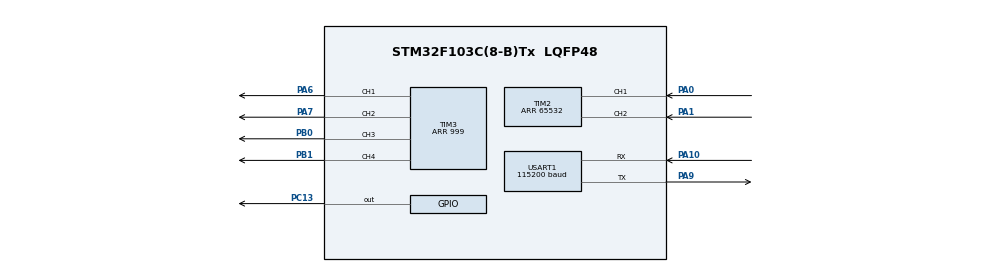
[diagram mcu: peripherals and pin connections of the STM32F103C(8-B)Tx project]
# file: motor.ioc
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Dma.Request0=USART1_RX
Dma.USART1_RX.0.Direction=DMA_PERIPH_TO_MEMORY
Dma.USART1_RX.0.Instance=DMA1_Channel5
Dma.USART1_RX.0.MemDataAlignment=DMA_MDATAALIGN_BYTE
Dma.USART1_RX.0.MemInc=DMA_MINC_ENABLE
Dma.USART1_RX.0.Mode=DMA_CIRCULAR
Dma.USART1_RX.0.PeriphDataAlignment=DMA_PDATAALIGN_BYTE
Dma.USART1_RX.0.PeriphInc=DMA_PINC_DISABLE
Dma.USART1_RX.0.Priority=DMA_PRIORITY_LOW
Mcu.Family=STM32F1
Mcu.Name=STM32F103C(8-B)Tx
Mcu.Package=LQFP48
NVIC.DMA1_Channel5_IRQn=true\:0\:0\:false\:false\:true\:false\:true\:true
NVIC.PriorityGroup=NVIC_PRIORITYGROUP_4
NVIC.USART1_IRQn=true\:0\:0\:false\:false\:true\:true\:true\:true
PA0-WKUP.Signal=S_TIM2_CH1_ETR
PA1.Signal=S_TIM2_CH2
PA10.GPIO_PuPd=GPIO_PULLUP
PA10.Mode=Asynchronous
PA10.Signal=USART1_RX
PA13.Mode=Serial_Wire
PA13.Signal=SYS_JTMS-SWDIO
PA14.Mode=Serial_Wire
PA14.Signal=SYS_JTCK-SWCLK
PA6.Signal=S_TIM3_CH1
PA7.Signal=S_TIM3_CH2
PA9.Mode=Asynchronous
PA9.Signal=USART1_TX
PB0.Signal=S_TIM3_CH3
PB1.Signal=S_TIM3_CH4
PC13-TAMPER-RTC.GPIO_ModeDefaultOutputPP=GPIO_MODE_OUTPUT_OD
PC13-TAMPER-RTC.GPIO_PuPd=GPIO_NOPULL
PC13-TAMPER-RTC.Signal=GPIO_Output
ProjectManager.HeapSize=0x200
ProjectManager.StackSize=0x400
ProjectManager.TargetToolchain=CMake
RCC.APB1Freq_Value=8000000
RCC.APB2Freq_Value=8000000
SH.S_TIM2_CH1_ETR.0=TIM2_CH1,Encoder_Interface
SH.S_TIM2_CH2.0=TIM2_CH2,Encoder_Interface
SH.S_TIM3_CH1.0=TIM3_CH1,PWM Generation1 CH1
SH.S_TIM3_CH2.0=TIM3_CH2,PWM Generation2 CH2
SH.S_TIM3_CH3.0=TIM3_CH3,PWM Generation3 CH3
SH.S_TIM3_CH4.0=TIM3_CH4,PWM Generation4 CH4
TIM2.EncoderMode=TIM_ENCODERMODE_TI12
TIM2.Period=65532
TIM3.Channel-PWM\ Generation1\ CH1=TIM_CHANNEL_1
TIM3.Channel-PWM\ Generation2\ CH2=TIM_CHANNEL_2
TIM3.Channel-PWM\ Generation3\ CH3=TIM_CHANNEL_3
TIM3.Channel-PWM\ Generation4\ CH4=TIM_CHANNEL_4
TIM3.Period=999
USART1.BaudRate=115200
USART1.VirtualMode=VM_ASYNC
VP_TIM3_VS_ClockSourceINT.Mode=Internal
board=custom

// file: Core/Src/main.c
/* USER CODE BEGIN Header */
/**
  ******************************************************************************
  * @file           : main.c
  * @brief          : Main program body
  ******************************************************************************
  * @attention
  *
  * Copyright (c) 2026 STMicroelectronics.
  * All rights reserved.
  *
  * This software is licensed under terms that can be found in the LICENSE file
  * in the root directory of this software component.
  * If no LICENSE file comes with this software, it is provided AS-IS.
  *
  ******************************************************************************
  */
/* USER CODE END Header */
#include "main.h"

/* USER CODE BEGIN Includes */

#include "USART_self.h"

/* USER CODE END Includes */

TIM_HandleTypeDef htim2;
TIM_HandleTypeDef htim3;

UART_HandleTypeDef huart1;
DMA_HandleTypeDef hdma_usart1_rx;

/* USER CODE BEGIN PV */

static USART_T uart1;

/* USER CODE END PV */

void SystemClock_Config(void);
static void MX_GPIO_Init(void);
static void MX_DMA_Init(void);
static void MX_USART1_UART_Init(void);
static void MX_TIM2_Init(void);
static void MX_TIM3_Init(void);

/* USER CODE BEGIN 0 */

//void HAL_UART_RxCpltCallback(UART_HandleTypeDef *huart){
//  USART_RxCpltHandler(huart);
//}

/* USER CODE END 0 */

int main(void)
{

  /* MCU Configuration--------------------------------------------------------*/

  /* Reset of all peripherals, Initializes the Flash interface and the Systick. */
  HAL_Init();

  /* Configure the system clock */
  SystemClock_Config();

  /* Initialize all configured peripherals */
  MX_GPIO_Init();
  MX_DMA_Init();
  MX_USART1_UART_Init();
  MX_TIM2_Init();
  MX_TIM3_Init();
  /* USER CODE BEGIN 2 */

  USART_Init(&uart1,&huart1);

  //uint8_t test_data[4]={0x01,0x02,0x03,0x04};

  HAL_TIM_Encoder_Start(&htim2, TIM_CHANNEL_1);
  HAL_TIM_Encoder_Start(&htim2, TIM_CHANNEL_2);
  uint32_t TIME=0;
  uint16_t CNT;
  float Send_t;
  float Send;
  float speed;

  /* USER CODE END 2 */

  /* Infinite loop */
  /* USER CODE BEGIN WHILE */
  while (1)
  {

    //USART_Send(&uart1,test_data,4);

    //int i=USART_ReadByte(&uart1);
    //if(i>0) {
    //  uint8_t data=i;
    //  USART_Send(&uart1,&data,1);
    //}

    //SendVOFA(&uart1,0x00,1);

  //if (HAL_GetTick()>=TIME) {
  //  TIME=TIME+10;
  //
  //  CNT=__HAL_TIM_GET_COUNTER(&htim2);
  //
  //
  //  Send=(float)CNT/1330*360;
  //
  //  speed=(Send-Send_t)/0.01;
  //
  //  SendVOFA(&uart1,&speed,1);
  //
  //  Send_t=Send;
  //}

    int a=USART_ReadByte(&uart1);
    if (a>0) {
      uint8_t send=a;
      USART_Send(&uart1,&send,1);
    }

    /* USER CODE END WHILE */

  }
}

void SystemClock_Config(void)
{
  RCC_OscInitTypeDef RCC_OscInitStruct = {0};
  RCC_ClkInitTypeDef RCC_ClkInitStruct = {0};

  /** Initializes the RCC Oscillators according to the specified parameters
  * in the RCC_OscInitTypeDef structure.
  */
  RCC_OscInitStruct.OscillatorType = RCC_OSCILLATORTYPE_HSI;
  RCC_OscInitStruct.HSIState = RCC_HSI_ON;
  RCC_OscInitStruct.HSICalibrationValue = RCC_HSICALIBRATION_DEFAULT;
  RCC_OscInitStruct.PLL.PLLState = RCC_PLL_NONE;
  if (HAL_RCC_OscConfig(&RCC_OscInitStruct) != HAL_OK)
  {
    Error_Handler();
  }

  /** Initializes the CPU, AHB and APB buses clocks
  */
  RCC_ClkInitStruct.ClockType = RCC_CLOCKTYPE_HCLK|RCC_CLOCKTYPE_SYSCLK
                              |RCC_CLOCKTYPE_PCLK1|RCC_CLOCKTYPE_PCLK2;
  RCC_ClkInitStruct.SYSCLKSource = RCC_SYSCLKSOURCE_HSI;
  RCC_ClkInitStruct.AHBCLKDivider = RCC_SYSCLK_DIV1;
  RCC_ClkInitStruct.APB1CLKDivider = RCC_HCLK_DIV1;
  RCC_ClkInitStruct.APB2CLKDivider = RCC_HCLK_DIV1;

  if (HAL_RCC_ClockConfig(&RCC_ClkInitStruct, FLASH_LATENCY_0) != HAL_OK)
  {
    Error_Handler();
  }
}

static void MX_TIM2_Init(void)
{

  TIM_Encoder_InitTypeDef sConfig = {0};
  TIM_MasterConfigTypeDef sMasterConfig = {0};

  htim2.Instance = TIM2;
  htim2.Init.Prescaler = 0;
  htim2.Init.CounterMode = TIM_COUNTERMODE_UP;
  htim2.Init.Period = 65532;
  htim2.Init.ClockDivision = TIM_CLOCKDIVISION_DIV1;
  htim2.Init.AutoReloadPreload = TIM_AUTORELOAD_PRELOAD_DISABLE;
  sConfig.EncoderMode = TIM_ENCODERMODE_TI12;
  sConfig.IC1Polarity = TIM_ICPOLARITY_RISING;
  sConfig.IC1Selection = TIM_ICSELECTION_DIRECTTI;
  sConfig.IC1Prescaler = TIM_ICPSC_DIV1;
  sConfig.IC1Filter = 0;
  sConfig.IC2Polarity = TIM_ICPOLARITY_RISING;
  sConfig.IC2Selection = TIM_ICSELECTION_DIRECTTI;
  sConfig.IC2Prescaler = TIM_ICPSC_DIV1;
  sConfig.IC2Filter = 0;
  if (HAL_TIM_Encoder_Init(&htim2, &sConfig) != HAL_OK)
  {
    Error_Handler();
  }
  sMasterConfig.MasterOutputTrigger = TIM_TRGO_RESET;
  sMasterConfig.MasterSlaveMode = TIM_MASTERSLAVEMODE_DISABLE;
  if (HAL_TIMEx_MasterConfigSynchronization(&htim2, &sMasterConfig) != HAL_OK)
  {
    Error_Handler();
  }

}

static void MX_TIM3_Init(void)
{

  TIM_ClockConfigTypeDef sClockSourceConfig = {0};
  TIM_MasterConfigTypeDef sMasterConfig = {0};
  TIM_OC_InitTypeDef sConfigOC = {0};

  htim3.Instance = TIM3;
  htim3.Init.Prescaler = 0;
  htim3.Init.CounterMode = TIM_COUNTERMODE_UP;
  htim3.Init.Period = 999;
  htim3.Init.ClockDivision = TIM_CLOCKDIVISION_DIV1;
  htim3.Init.AutoReloadPreload = TIM_AUTORELOAD_PRELOAD_DISABLE;
  if (HAL_TIM_Base_Init(&htim3) != HAL_OK)
  {
    Error_Handler();
  }
  sClockSourceConfig.ClockSource = TIM_CLOCKSOURCE_INTERNAL;
  if (HAL_TIM_ConfigClockSource(&htim3, &sClockSourceConfig) != HAL_OK)
  {
    Error_Handler();
  }
  if (HAL_TIM_PWM_Init(&htim3) != HAL_OK)
  {
    Error_Handler();
  }
  sMasterConfig.MasterOutputTrigger = TIM_TRGO_RESET;
  sMasterConfig.MasterSlaveMode = TIM_MASTERSLAVEMODE_DISABLE;
  if (HAL_TIMEx_MasterConfigSynchronization(&htim3, &sMasterConfig) != HAL_OK)
  {
    Error_Handler();
  }
  sConfigOC.OCMode = TIM_OCMODE_PWM1;
  sConfigOC.Pulse = 0;
  sConfigOC.OCPolarity = TIM_OCPOLARITY_HIGH;
  sConfigOC.OCFastMode = TIM_OCFAST_DISABLE;
  if (HAL_TIM_PWM_ConfigChannel(&htim3, &sConfigOC, TIM_CHANNEL_1) != HAL_OK)
  {
    Error_Handler();
  }
  if (HAL_TIM_PWM_ConfigChannel(&htim3, &sConfigOC, TIM_CHANNEL_2) != HAL_OK)
  {
    Error_Handler();
  }
  if (HAL_TIM_PWM_ConfigChannel(&htim3, &sConfigOC, TIM_CHANNEL_3) != HAL_OK)
  {
    Error_Handler();
  }
  if (HAL_TIM_PWM_ConfigChannel(&htim3, &sConfigOC, TIM_CHANNEL_4) != HAL_OK)
  {
    Error_Handler();
  }
  HAL_TIM_MspPostInit(&htim3);

}

static void MX_USART1_UART_Init(void)
{

  huart1.Instance = USART1;
  huart1.Init.BaudRate = 115200;
  huart1.Init.WordLength = UART_WORDLENGTH_8B;
  huart1.Init.StopBits = UART_STOPBITS_1;
  huart1.Init.Parity = UART_PARITY_NONE;
  huart1.Init.Mode = UART_MODE_TX_RX;
  huart1.Init.HwFlowCtl = UART_HWCONTROL_NONE;
  huart1.Init.OverSampling = UART_OVERSAMPLING_16;
  if (HAL_UART_Init(&huart1) != HAL_OK)
  {
    Error_Handler();
  }

}

static void MX_DMA_Init(void)
{

  /* DMA controller clock enable */
  __HAL_RCC_DMA1_CLK_ENABLE();

  /* DMA interrupt init */
  /* DMA1_Channel5_IRQn interrupt configuration */
  HAL_NVIC_SetPriority(DMA1_Channel5_IRQn, 0, 0);
  HAL_NVIC_EnableIRQ(DMA1_Channel5_IRQn);

}

static void MX_GPIO_Init(void)
{
  GPIO_InitTypeDef GPIO_InitStruct = {0};

  /* GPIO Ports Clock Enable */
  __HAL_RCC_GPIOC_CLK_ENABLE();
  __HAL_RCC_GPIOA_CLK_ENABLE();
  __HAL_RCC_GPIOB_CLK_ENABLE();

  /*Configure GPIO pin Output Level */
  HAL_GPIO_WritePin(GPIOC, GPIO_PIN_13, GPIO_PIN_RESET);

  /*Configure GPIO pin : PC13 */
  GPIO_InitStruct.Pin = GPIO_PIN_13;
  GPIO_InitStruct.Mode = GPIO_MODE_OUTPUT_OD;
  GPIO_InitStruct.Pull = GPIO_NOPULL;
  GPIO_InitStruct.Speed = GPIO_SPEED_FREQ_LOW;
  HAL_GPIO_Init(GPIOC, &GPIO_InitStruct);

}

void Error_Handler(void)
{
  __disable_irq();
  while (1)
  {
  }
}
